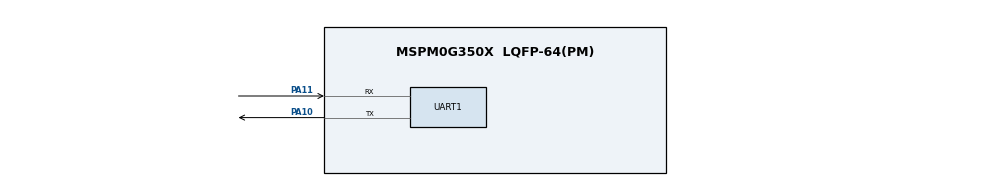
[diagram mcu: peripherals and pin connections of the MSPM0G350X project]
/**
 * @cliArgs --device "MSPM0G350X" --part "Default" --package "LQFP-64(PM)" --product "mspm0_sdk@2.05.00.05"
 * @versions {"tool":"1.24.0+4110"}
 */

/**
 * Import the modules used in this configuration.
 */
const GPIO    = scripting.addModule("/ti/driverlib/GPIO", {}, false);
const GPIO1   = GPIO.addInstance();
const SYSCTL  = scripting.addModule("/ti/driverlib/SYSCTL");
const SYSTICK = scripting.addModule("/ti/driverlib/SYSTICK");
const UART    = scripting.addModule("/ti/driverlib/UART", {}, false);
const UART1   = UART.addInstance();

/**
 * Write custom configuration values to the imported modules.
 */
GPIO1.$name                              = "LED";
GPIO1.port                               = "PORTB";
GPIO1.associatedPins[0].$name            = "LED_1";
GPIO1.associatedPins[0].internalResistor = "PULL_DOWN";
GPIO1.associatedPins[0].assignedPin      = "2";

const Board = scripting.addModule("/ti/driverlib/Board", {}, false);

SYSCTL.forceDefaultClkConfig = true;

SYSTICK.periodEnable    = true;
SYSTICK.period          = 32000;
SYSTICK.interruptEnable = true;
SYSTICK.systickEnable   = true;

UART1.$name                    = "UART_0";
UART1.targetBaudRate           = 115200;
UART1.enabledInterrupts        = ["RX"];
UART1.peripheral.rxPin.$assign = "PA11";
UART1.peripheral.txPin.$assign = "PA10";
UART1.txPinConfig.$name        = "ti_driverlib_gpio_GPIOPinGeneric0";
UART1.rxPinConfig.$name        = "ti_driverlib_gpio_GPIOPinGeneric1";

/**
 * Pinmux solution for unlocked pins/peripherals. This ensures that minor changes to the automatic solver in a future
 * version of the tool will not impact the pinmux you originally saw.  These lines can be completely deleted in order to
 * re-solve from scratch.
 */
GPIO1.associatedPins[0].pin.$suggestSolution = "PB2";
Board.peripheral.$suggestSolution            = "DEBUGSS";
Board.peripheral.swclkPin.$suggestSolution   = "PA20";
Board.peripheral.swdioPin.$suggestSolution   = "PA19";
SYSCTL.peripheral.$suggestSolution           = "SYSCTL";
UART1.peripheral.$suggestSolution            = "UART0";
